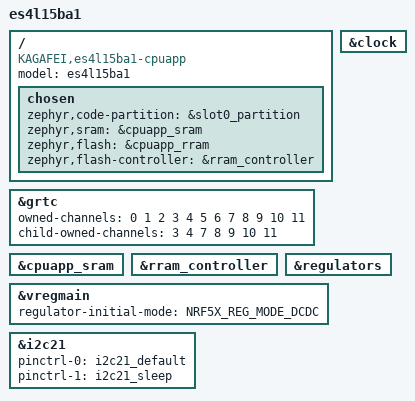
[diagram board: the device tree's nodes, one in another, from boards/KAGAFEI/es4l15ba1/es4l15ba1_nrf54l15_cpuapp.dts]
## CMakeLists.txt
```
cmake_minimum_required(VERSION 3.20.0)

# The kneil_tinyml library (src/kneil_*.c, include/, zephyr/module.yml) is in this folder,
# so this folder is also its Zephyr module. The library builds only if CONFIG_KNEIL_TINYML=y.
list(APPEND ZEPHYR_EXTRA_MODULES ${CMAKE_CURRENT_SOURCE_DIR})

find_package(Zephyr REQUIRED HINTS $ENV{ZEPHYR_BASE})

project(neilv2)

if(CONFIG_NEIL_APP_KNEIL_LIVE)
    # KNEIL live build (kneil.conf): activity classifier and live stream over BLE
    target_sources(app PRIVATE
        src/kneil_live.c
        src/bma580_fifo.c
        protocol/kneil_proto.c
    )
    target_include_directories(app PRIVATE protocol)

    # Model size for the INFO lines, counted in the generated headers (never edited): a tree with
    # k decisions has 2k+1 nodes. CMake runs again if a model header changes.
    foreach(model forest tree)
        set(model_h ${CMAKE_CURRENT_SOURCE_DIR}/include/kneil_model_${model}.h)
        file(STRINGS ${model_h} decisions REGEX "if \\(features\\[")
        file(STRINGS ${model_h} trees REGEX "int32_t kneil_model_tree_[0-9]+\\(")
        list(LENGTH decisions n_decisions)
        list(LENGTH trees n_trees)
        math(EXPR n_nodes "2 * ${n_decisions} + ${n_trees}")
        string(TOUPPER ${model} MODEL)
        target_compile_definitions(app PRIVATE KNEIL_${MODEL}_TREES=${n_trees} KNEIL_${MODEL}_NODES=${n_nodes})
        set_property(DIRECTORY APPEND PROPERTY CMAKE_CONFIGURE_DEPENDS ${model_h})
    endforeach()
else()
    # NeiL BLE sensor app
    target_sources(app PRIVATE
        src/main.c
        src/rtc.c
        src/bma580.c
        src/TEMP118.c
    )
endif()

target_include_directories(app PRIVATE src)
```

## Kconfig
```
# NeiL application options. The kneil_tinyml library options are in zephyr/Kconfig.

config NEIL_APP_KNEIL_LIVE
	bool "KNEIL live app (src/kneil_live.c) instead of the NeiL BLE app (src/main.c)"
	help
	  Set in kneil.conf. Runs the kneil_tinyml activity classifier on the
	  BMA580 data and streams the results (KNEIL live protocol).

source "Kconfig.zephyr"
```

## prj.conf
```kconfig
# Console and Debug (for development - disable for production)
CONFIG_CONSOLE=n
CONFIG_PRINTK=n
CONFIG_RTT_CONSOLE=n
CONFIG_USE_SEGGER_RTT=n
CONFIG_SERIAL=n
CONFIG_UART_CONSOLE=n
CONFIG_LOG=n
CONFIG_ASSERT=n
CONFIG_DEBUG=n

# I2C Configuration
CONFIG_I2C=y

# 32kHz clock source: this module has no external 32.768kHz crystal fitted
# (see datasheet section 12, "Notes"), so the SoftDevice Controller/MPSL must
# be told to use the internal RC oscillator instead of an XTAL. Without this,
# the build fails in mpsl_init.c with "Clock source is not supported or not
# defined".
CONFIG_CLOCK_CONTROL_NRF_K32SRC_RC=y
CONFIG_CLOCK_CONTROL_NRF_K32SRC_RC_CALIBRATION=y
CONFIG_CLOCK_CONTROL_NRF_K32SRC_500PPM=y

# Bluetooth Configuration
# NOTE: CONFIG_BT_LL_SOFTDEVICE is selected by default on nRF54L, unlike the
# nRF52832 build this project was ported from (which used the Zephyr
# BT_LL_SW_SPLIT controller). TX power is therefore set with
# BT_CTLR_TX_PWR_ANTENNA (dBm) instead of the BT_CTLR_TX_PWR_PLUS_x choice.
CONFIG_BT=y
CONFIG_BT_DEVICE_NAME="NeiL V3"
CONFIG_BT_PERIPHERAL=y
CONFIG_BT_GATT_DYNAMIC_DB=n
CONFIG_BT_GATT_CACHING=n
CONFIG_BT_AUTO_PHY_UPDATE=n
CONFIG_BT_DATA_LEN_UPDATE=n
CONFIG_BT_SETTINGS=n
CONFIG_SETTINGS=n

# Power: without a preferred connection interval, most centrals (esp. iOS)
# default to a fast ~30-50ms interval, keeping the radio active far more
# often than this app needs (send_data_thread only has new data every
# NOTIFY_INTERVAL=100ms). CONFIG_BT_GAP_AUTO_UPDATE_CONN_PARAMS defaults to y
# and was previously being force-disabled here, which meant these preferred
# values were also never requested to the central.
CONFIG_BT_GAP_AUTO_UPDATE_CONN_PARAMS=y
CONFIG_BT_PERIPHERAL_PREF_MIN_INT=80
CONFIG_BT_PERIPHERAL_PREF_MAX_INT=160
CONFIG_BT_PERIPHERAL_PREF_LATENCY=0
CONFIG_BT_PERIPHERAL_PREF_TIMEOUT=400

# Reduce CPU frequency when idle
CONFIG_SYS_CLOCK_TICKS_PER_SEC=100

# Disable features not needed
CONFIG_TIMESLICING=n

# Sensor Support
CONFIG_SENSOR=y

# GPIO Configuration
CONFIG_GPIO=n

# Standard C Library
CONFIG_NEWLIB_LIBC=y

# Power Management
# NOTE: CONFIG_PM/CONFIG_PM_DEVICE are left out here: the nRF54L SoC family
# does not select HAS_PM in this NCS version (only nRF54H does), so setting
# them is a silently-dropped no-op that just produces a Kconfig warning.
CONFIG_HWINFO=y
CONFIG_POWEROFF=y

# Bluetooth Device Information Service
# NOTE: CONFIG_BT_DIS_MANUF/CONFIG_BT_DIS_MODEL are deprecated in this Zephyr
# version; use the *_NAME_STR / *_NUMBER_STR equivalents instead.
CONFIG_BT_DIS=y
CONFIG_BT_DIS_MANUF_NAME_STR="NEIL TECH LTD"
CONFIG_BT_DIS_MODEL_NUMBER_STR="NeiL V01"

# Memory optimization
CONFIG_MAIN_STACK_SIZE=2048

# ===== POWER OPTIMIZATION SETTINGS =====
# Request +4 dBm TX power (SoftDevice Controller antenna power, in dBm)
CONFIG_BT_CTLR_TX_PWR_ANTENNA=4
```

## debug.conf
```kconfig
# Debug overlay: re-enables the RTT console/printk/logging that prj.conf
# turns off for the power-optimized production build. Build with this on top
# of prj.conf, e.g.:
#   west build -b es4l15ba1/nrf54l15/cpuapp -- -DEXTRA_CONF_FILE=debug.conf
CONFIG_CONSOLE=y
CONFIG_PRINTK=y
CONFIG_USE_SEGGER_RTT=y
CONFIG_RTT_CONSOLE=y
CONFIG_LOG=y
CONFIG_ASSERT=y
CONFIG_DEBUG=y

# Needed for the RTC INT-pin GPIO monitoring diagnostic (main.c int_gpio).
CONFIG_GPIO=y

# The default 1 kB RTT up-buffer overflows during the dense boot-time sensor
# probe (the host logger only drains ~2 kB/s), silently dropping lines.
CONFIG_SEGGER_RTT_BUFFER_SIZE_UP=8192
```

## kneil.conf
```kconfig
# KNEIL live build for the es4l15ba1 board: activity classifier (kneil_tinyml, model V3).
# Use it on top of prj.conf, in its own build folder (the NeiL app in main.c is not changed):
#   west build -d build_kneil -b es4l15ba1/nrf54l15/cpuapp . -- -DBOARD_ROOT=. -DEXTRA_CONF_FILE=kneil.conf

# Build src/kneil_live.c instead of src/main.c
CONFIG_NEIL_APP_KNEIL_LIVE=y

# kneil_tinyml library
CONFIG_KNEIL_TINYML=y
CONFIG_KNEIL_TINYML_FS_HZ=50
CONFIG_KNEIL_TINYML_SELFTEST=y
CONFIG_FPU=y
CONFIG_FPU_SHARING=y

# Bluetooth LE: advertises KNEIL-xxxx with the KNEIL live service (LIVE, RAW, CONTROL).
# ATT MTU 247 and data length extension (prj.conf turns these updates off for the NeiL app).
CONFIG_BT_DEVICE_NAME_DYNAMIC=y
CONFIG_BT_DEVICE_NAME_MAX=16
CONFIG_BT_L2CAP_TX_MTU=247
CONFIG_BT_BUF_ACL_TX_SIZE=251
CONFIG_BT_BUF_ACL_RX_SIZE=251
CONFIG_BT_CTLR_DATA_LENGTH_MAX=251
CONFIG_BT_DATA_LEN_UPDATE=y
CONFIG_BT_AUTO_PHY_UPDATE=y
# margin for the Bluetooth RX thread (GATT callbacks run on it; 1024 overflowed once)
CONFIG_BT_RX_STACK_SIZE=2048

# A fault restarts the board instead of halting it (the bridge reconnects by itself); the fault report
# is printed on RTT and the INFO summary shows the reset cause.
CONFIG_RESET_ON_FATAL_ERROR=y
CONFIG_LOG=y
CONFIG_LOG_MODE_MINIMAL=y
CONFIG_LOG_DEFAULT_LEVEL=2

# Diagnostics only over SEGGER RTT (this board has no UART or USB; tests use BLE and the bridge)
CONFIG_CONSOLE=y
CONFIG_PRINTK=y
CONFIG_USE_SEGGER_RTT=y
CONFIG_RTT_CONSOLE=y
CONFIG_SEGGER_RTT_BUFFER_SIZE_UP=4096
```

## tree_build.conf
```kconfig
# Extra Kconfig fragment for the single-tree KNEIL live build (adds to kneil.conf):
#   west build -d build_kneil_tree -b es4l15ba1/nrf54l15/cpuapp . --pristine=always -- \
#       "-DBOARD_ROOT=<absolute path of this folder>" "-DEXTRA_CONF_FILE=kneil.conf;tree_build.conf"
CONFIG_KNEIL_TINYML_MODEL_SMALL=y
```

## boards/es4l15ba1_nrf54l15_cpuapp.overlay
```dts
/*
 * App-level overlay for the custom board: run the I2C bus at 100 kHz
 * (I2C_BITRATE_STANDARD) instead of the driver default, to rule out bus
 * speed as a factor while debugging the sensors. Pin assignment and
 * everything else still comes from the board's own devicetree.
 */

&i2c21 {
	clock-frequency = <I2C_BITRATE_STANDARD>;
};
```

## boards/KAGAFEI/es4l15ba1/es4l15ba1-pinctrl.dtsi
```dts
&pinctrl {
	i2c21_default: i2c21_default {
		group1 {
			psels = <NRF_PSEL(TWIM_SDA, 1, 7)>,
					<NRF_PSEL(TWIM_SCL, 1, 6)>;
			bias-pull-up;
		};
	};

	i2c21_sleep: i2c21_sleep {
		group1 {
			psels = <NRF_PSEL(TWIM_SDA, 1, 7)>,
					<NRF_PSEL(TWIM_SCL, 1, 6)>;
			low-power-enable;
		};
	};
};
```

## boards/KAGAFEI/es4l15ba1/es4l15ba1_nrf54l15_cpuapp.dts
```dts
/dts-v1/;
#include <nordic/nrf54l15_cpuapp.dtsi>
#include <zephyr/dt-bindings/gpio/gpio.h>
#include <zephyr/dt-bindings/i2c/i2c.h>
#include "es4l15ba1-pinctrl.dtsi"

/ {
	model = "es4l15ba1";
	compatible = "KAGAFEI,es4l15ba1-cpuapp";

	chosen {
		zephyr,code-partition = &slot0_partition;
		zephyr,sram = &cpuapp_sram;
		zephyr,flash = &cpuapp_rram;
		zephyr,flash-controller = &rram_controller;
	};
};

&grtc {
	owned-channels = <0 1 2 3 4 5 6 7 8 9 10 11>;
	/* Channels 7-11 reserved for Zero Latency IRQs, 3-4 for FLPR */
	child-owned-channels = <3 4 7 8 9 10 11>;
	status = "okay";
};

&cpuapp_sram {
	status = "okay";
};

&rram_controller {
	status = "okay";
};

/*
 * Required for the CLOCK_CONTROL_NRF Kconfig menu (32kHz clock source
 * selection) to be visible at all - see prj.conf for why the RC oscillator
 * is selected as the LFCLK source on this crystal-less module.
 */
&clock {
	status = "okay";
};

/*
 * Switch the main regulator from the default LDO to DC/DC mode. The
 * datasheet requires a 4.7uH inductor across PAD2 (DECD) / PAD21 (DCC) for
 * exactly this purpose (section 11.2.3) - without this, that inductor is
 * populated on the board but unused, and the SoC runs on the less efficient
 * LDO the whole time, most noticeably during radio TX.
 */
&regulators {
	status = "okay";
};

&vregmain {
	status = "okay";
	regulator-initial-mode = <NRF5X_REG_MODE_DCDC>;
};

&i2c21 {
	status = "okay";
	pinctrl-0 = <&i2c21_default>;
	pinctrl-1 = <&i2c21_sleep>;
	pinctrl-names = "default", "sleep";
};

#include <nordic/nrf54l15_partition.dtsi>
```

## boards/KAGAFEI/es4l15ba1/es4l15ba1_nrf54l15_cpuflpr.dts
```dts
/dts-v1/;
#include <nordic/nrf54l15_cpuflpr.dtsi>
#include "es4l15ba1-pinctrl.dtsi"

/ {
	model = "es4l15ba1";
	compatible = "KAGAFEI,es4l15ba1-cpuflpr";

	chosen {
		zephyr,code-partition = &cpuflpr_code_partition;
		zephyr,flash = &cpuflpr_rram;
		zephyr,sram = &cpuflpr_sram;
	};
};

&cpuflpr_sram {
	status = "okay";
	reg = <0x20028000 DT_SIZE_K(96)>;
	ranges = <0x0 0x20028000 DT_SIZE_K(96)>;
};

&cpuflpr_rram {
	partitions {
		compatible = "fixed-partitions";
		#address-cells = <1>;
		#size-cells = <1>;

		cpuflpr_code_partition: partition@0 {
			label = "image-0";
			reg = <0x0 DT_SIZE_K(96)>;
		};
	};
};

&grtc {
	owned-channels = <3 4>;
	status = "okay";
};
```

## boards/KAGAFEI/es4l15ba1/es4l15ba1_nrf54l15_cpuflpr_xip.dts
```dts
#include "es4l15ba1_nrf54l15_cpuflpr.dts"

/ {
	compatible = "KAGAFEI,es4l15ba1-cpuflpr-xip";
};

&cpuflpr_sram {
	reg = <0x2002f000 DT_SIZE_K(68)>;
	ranges = <0x0 0x2002f000 DT_SIZE_K(68)>;
};
```

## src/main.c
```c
#include <zephyr/kernel.h>
#include <zephyr/device.h>
#include <zephyr/drivers/i2c.h>
#include <zephyr/sys/printk.h>
#include "bma580.h"
#include "TEMP118.h"
#include "RTC.h"
#include <zephyr/types.h>
#include <stddef.h>
#include <string.h>
#include <zephyr/bluetooth/bluetooth.h>
#include <zephyr/bluetooth/gap.h>
#include <zephyr/sys/printk.h>
#include <zephyr/sys/byteorder.h>
#include <zephyr/bluetooth/uuid.h>
#include <zephyr/bluetooth/gatt.h>

#include <zephyr/drivers/gpio.h>
#include <zephyr/drivers/hwinfo.h>
#include <zephyr/drivers/comparator.h>
#include <zephyr/pm/device.h>
#include <zephyr/sys/poweroff.h>
#include <zephyr/sys/util.h>

// Make sure the node label matches your device tree, e.g., "interrupt" or "button0"
//tatic const struct gpio_dt_spec sw0 = GPIO_DT_SPEC_GET(DT_NODELABEL(interrupt), gpios);
// If your device tree uses a different label (e.g., "button0"), use that instead:
// static const struct gpio_dt_spec sw0 = GPIO_DT_SPEC_GET(DT_NODELABEL(button0), gpios);

#define DEVICE_NAME     CONFIG_BT_DEVICE_NAME
#define DEVICE_NAME_LEN (sizeof(DEVICE_NAME) - 1)
#define NOTIFY_INTERVAL 100
// ES4L15BA1 (nRF54L15): I2C SCL/SDA are on P1.06/P1.07, wired to the i2c21
// TWIM/pinctrl instance in boards/KAGAFEI/es4l15ba1/es4l15ba1_nrf54l15_cpuapp.dts
// (the previous nRF52832 board used the "i2c0" node label instead).
#define I2C_DEV_NODE DT_NODELABEL(i2c21)
#define STACK_SIZE 1024
#define PRIORITY 5
#define BT_UUID_SENSOR_SERVICE_VAL \
	BT_UUID_128_ENCODE(0x00001000, 0x0000, 0x1000, 0x8000, 0x5f9b34fb)

// define DEF_SVC1_ADC_VAL_1_UUID_128      {0xFB, 0x34, 0x9B, 0x5F, 0x80, 0x00, 0x00, 0x80, 0x00, 0x10, 0x00, 0x00, 0x01, 0x10, 0x00, 0x00}
// 0000 1001-0000-1000-8000-00805F9B34FB
#define BT_UUID_SENSOR_CHAR_VAL \
	BT_UUID_128_ENCODE(0x00001001, 0x0000, 0x1000, 0x8000, 0x00805F9B34FB)

static bool notify_enabled = false;
static struct bt_uuid_128 sensor_service_uuid = BT_UUID_INIT_128(BT_UUID_SENSOR_SERVICE_VAL);
static struct bt_uuid_128 sensor_char_uuid = BT_UUID_INIT_128(BT_UUID_SENSOR_CHAR_VAL);
#define I2C_ADDR 0x18  // Replace with your target device address
static const uint8_t url_data[] = {
    0x17,'/' ,'/',
    'w','w','w','.','n','e','i','l','.','t','e','c','h','/'
};
static struct k_work adv_work;
static bool is_connected = false;
static uint8_t sensor_data[20];
static const struct bt_data ad[]={
	BT_DATA_BYTES(BT_DATA_UUID128_ALL, BT_UUID_SENSOR_SERVICE_VAL),
	BT_DATA_BYTES(BT_DATA_FLAGS, BT_LE_AD_GENERAL | BT_LE_AD_NO_BREDR),
	BT_DATA(BT_DATA_NAME_COMPLETE, DEVICE_NAME, DEVICE_NAME_LEN),
};

const struct device *i2c_dev = DEVICE_DT_GET(I2C_DEV_NODE);


static const struct bt_data sd[]={

	//BT_DATA_BYTES(BT_DATA_UUID128_ALL, BT_UUID_SENSOR_SERVICE_VAL),
	BT_DATA(BT_DATA_URI,url_data,sizeof(url_data)),

};
static const struct bt_le_adv_param *adv_param = BT_LE_ADV_PARAM(
	(BT_LE_ADV_OPT_CONN |
	 BT_LE_ADV_OPT_USE_IDENTITY),
	640,
	800,
	NULL);

/* Wakes send_data_thread when it may have work to do (connected AND
 * notifications enabled), instead of it polling is_connected/notify_enabled
 * on a 20ms timer. */
static K_SEM_DEFINE(notify_state_sem, 0, 1);

static void sensor_ccc_cfg_changed(const struct bt_gatt_attr *attr, uint16_t value)
{
	notify_enabled = (value & BT_GATT_CCC_NOTIFY);
	printk("Notify %s\n", notify_enabled ? "enabled" : "disabled");
	k_sem_give(&notify_state_sem);
}

BT_GATT_SERVICE_DEFINE(sensor_svc,
	BT_GATT_PRIMARY_SERVICE(&sensor_service_uuid),
	BT_GATT_CHARACTERISTIC(&sensor_char_uuid.uuid,
			           BT_GATT_CHRC_NOTIFY | BT_GATT_CHRC_READ,
                       BT_GATT_PERM_READ,
			       NULL, NULL, sensor_data),
	BT_GATT_CCC(sensor_ccc_cfg_changed,
		    BT_GATT_PERM_READ | BT_GATT_PERM_WRITE),
);


static void adv_work_handler(struct k_work *work){
	int err = bt_le_adv_start(adv_param, ad, ARRAY_SIZE(ad), sd, ARRAY_SIZE(sd));

	if (err) {
		printk("Advertising failed to start (err %d)\n", err);
		return;
	}

	printk("Advertising successfully started\n");
}

static void advertising_start(void){
	k_work_submit(&adv_work);
}
static void recycled_cb(void){
	printk("Connection object available from previous conn. Disconnect is complete!\n");
	advertising_start();
}

static void on_connected(struct bt_conn *conn, uint8_t err){
	if (err) {
		printk("Connection failed (err %u)\n", err);
		return;
	}
	/* Powering the sensors up costs ~100ms of blocking k_sleep()s, which is
	 * far too long to spend inside a Bluetooth callback - it stalls the BT
	 * RX thread. Just record the state and let send_data_thread do the work. */
	is_connected = true;
	k_sem_give(&notify_state_sem);
	printk("Connected\n");
}

static void on_disconnected(struct bt_conn *conn, uint8_t reason){
	is_connected = false;
	notify_enabled = false;
	/* Wake send_data_thread so it powers both sensors down. Doing it there
	 * rather than here also avoids racing with an in-flight sensor read. */
	k_sem_give(&notify_state_sem);
	printk("Disconnected (reason %u)\n", reason);
}

struct bt_conn_cb connection_callbacks = {
	.connected = on_connected,
	.disconnected = on_disconnected,
	.recycled = recycled_cb,
};

/* Tracks whether the two sensors are currently powered. Owned exclusively by
 * send_data_thread so that they are woken exactly once when a central
 * connects and shut down exactly once when it goes away. */
static bool sensors_on;

static void sensors_power_up(void)
{
	TMP_wakeup(i2c_dev);
	k_msleep(20);
	BMA580_init(i2c_dev);
	k_msleep(20);
	sensors_on = true;
	printk("Sensors powered up\n");
}

static void sensors_power_down(void)
{
	TMP_sleep(i2c_dev);
	BMA_sleep(i2c_dev);
	sensors_on = false;
	printk("Sensors powered down\n");
}

void send_data_thread(void)
{

	if (!device_is_ready(i2c_dev)) {
    printk("I2C device not ready!\n");
    return;
	}

	k_msleep(20);

	/* Nothing is connected at boot, so put both sensors into their idle
	 * state rather than leaving them in whatever mode they came up in -
	 * the TMP118 in particular powers up converting continuously. */
	sensors_power_down();

	while (1) {
		if (is_connected) {
			if (!sensors_on) {
				sensors_power_up();
			}

			if (notify_enabled) {
				uint8_t data_temp[2];
				uint8_t data_xyz[6];
				uint8_t packet[20] = {0};

				readAccel(i2c_dev, data_xyz);
				k_msleep(50);
				readTemp118(i2c_dev, data_temp);

				packet[3] = data_temp[0];
				packet[4] = data_temp[1];
				//uint8_t zero = 0;
				for (int i = 0; i < 6; i++) {
					packet[14 + i] = data_xyz[i];
				}
				memcpy(sensor_data, packet, sizeof(packet));
				bt_gatt_notify(NULL, &sensor_svc.attrs[2], sensor_data, sizeof(packet));
				k_sleep(K_MSEC(NOTIFY_INTERVAL));
				continue;
			}
		} else if (sensors_on) {
			sensors_power_down();
		}

		/* Either disconnected, or connected but not subscribed yet: there is
		 * nothing to sample until the connection/notify state changes. */
		k_sem_take(&notify_state_sem, K_FOREVER);
	}
}

K_THREAD_DEFINE(sensor_thread_id, STACK_SIZE,
		send_data_thread, NULL, NULL, NULL,
		PRIORITY, 0, 0);

/*void print_time_thread(void)
{
    if (!device_is_ready(i2c_dev)) {
        printk("I2C device not ready!\n");
        return;
    }

    while (1) {
        uint8_t seconds, minutes, hours, date, month, year;

        // Use the new RTC function
        RTC_read_time(i2c_dev, &seconds, &minutes, &hours, &date, &month, &year);

        // Convert BCD to decimal
        uint8_t sec = ((seconds >> 4) * 10) + (seconds & 0x0F);
        uint8_t min = ((minutes >> 4) * 10) + (minutes & 0x0F);
        uint8_t hr = ((hours >> 4) * 10) + (hours & 0x0F);
        uint8_t d = ((date >> 4) * 10) + (date & 0x0F);
        uint8_t mon = ((month >> 4) * 10) + (month & 0x0F);
        uint8_t yr = ((year >> 4) * 10) + (year & 0x0F);

        // Print time
        printk("RTC Time: 20%02d-%02d-%02d %02d:%02d:%02d\n",
               yr, mon, d, hr, min, sec);

        k_sleep(K_SECONDS(1));
    }
}

// Add thread definition before main()
K_THREAD_DEFINE(print_time_thread_id, STACK_SIZE,
        print_time_thread, NULL, NULL, NULL,
        PRIORITY, 0, 0);*/

int main(void)
{
	//printk("\n%s system off demo\n", CONFIG_BOARD);

	//*(volatile uint32_t *)0x40000578 = 1;

	//RTC_clkout_disable(i2c_dev);
	//RTC_enable_porie_interrupt(i2c_dev);


	int alarm_status;

	if (!device_is_ready(i2c_dev)) {
        printk("I2C device not ready!\n");
        return 0;
    }

	alarm_status = RTC_Check_Alarm(i2c_dev);
	RTC_debug_dump(i2c_dev, "boot, before set_datetime");
	if (alarm_status == 1){
		printk("Alarm Date not set\n");
		RTC_set_datetime(i2c_dev,2025,1,26,1,12,0,0);
		printk("\n Date set \n");
		RTC_debug_dump(i2c_dev, "after set_datetime");
	}

	int err = bt_enable(NULL);

	if (err){
		printk("BLE Intialise Fail\n");
	}
	printk("Bluetooth initialized\n");
	bt_conn_cb_register(&connection_callbacks);
	k_work_init(&adv_work, adv_work_handler);
	advertising_start();

	k_sleep(K_SECONDS(20)); // Run for 1200 seconds 20 minutes
	// RTC_Start_CountDown(i2c_dev);
	k_thread_abort(sensor_thread_id);
	/* The thread owned the sensors; now that it is gone, make sure they are
	 * idle in case the load switch does not actually cut power. */
	sensors_power_down();

	if (alarm_status == 1){
		RTC_alarm_init(i2c_dev,1);
	}
	else {
		RTC_recover_int(i2c_dev);
	}
	RTC_debug_dump(i2c_dev, "after alarm branch");
	return 0;
	/*
	 * The RTC's alarm output isn't wired to this MCU - it drives a load
	 * switch that cuts power to this whole board. There is therefore no
	 * wake source for this SoC to arm: once the switch re-applies power,
	 * the SoC just goes through a normal power-on reset and main() runs
	 * again from scratch. All that's left to do here is stop spending
	 * power for however long remains until the RTC's alarm actually
	 * fires and the switch cuts power, so disable BLE and drop into the
	 * lowest-current System OFF state.
	 */
	//bt_disable();
	//sys_poweroff();
}
```

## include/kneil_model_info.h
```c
/* Written by stage3.py (KNEIL virtual implant) together with the model headers. */
#ifndef KNEIL_MODEL_INFO_H
#define KNEIL_MODEL_INFO_H
#define KNEIL_MODEL_FS_HZ 50          /* the models were trained on 50 Hz data */
#define KNEIL_MODEL_N_FEATURES 20
#define KNEIL_MODEL_LOWPASS_HZ 6      /* input low-pass used in training, applied on the device (0 = off) */
#define KNEIL_MODEL_DATASET "kneil_dataset_v1_6; kneil_camargo_v1_3; caicedo_2020; real implant-site (CeTI, KneE-PAD, MHEALTH, Marpino, PAMAP2, WearGait-PD); V3"
#endif
```

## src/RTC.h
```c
#ifndef RTC_H
#define RTC_H


#include <stdint.h>
#include <zephyr/device.h>

//void RTC_init_ContDown(const struct device *dev);
//void RTC_Start_CountDown(const struct device *dev);

int RTC_set_datetime(const struct device *i2c,
                     uint16_t year, uint8_t month, uint8_t date, uint8_t weekday,
                     uint8_t hour24, uint8_t minute, uint8_t second);
int RTC_alarm_init(const struct device *dev, uint8_t mins);

//void RTC_alarm_set(const struct device *dev);
//void RTC_recover_int(const struct device *dev);

int RTC_clkout_disable(const struct device *dev);

int RTC_enable_porie_interrupt(const struct device *dev);

int RTC_set_to_build_time(const struct device *i2c);

void RTC_read_time(const struct device *dev, uint8_t *seconds, uint8_t *minutes,
                   uint8_t *hours, uint8_t *date, uint8_t *month, uint8_t *year);

int RTC_Check_Alarm(const struct device *dev);

void RTC_recover_int(const struct device *dev);

void RTC_debug_dump(const struct device *dev, const char *label);
#endif
```

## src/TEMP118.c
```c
#include "TEMP118.h"
#include <zephyr/kernel.h>
#include <zephyr/device.h>
#include <zephyr/drivers/i2c.h>
#include <zephyr/sys/printk.h>
#include <string.h>

#define Temp_Data            0x00
#define TEMP118_Addr         0x49
#define TEMP118_config       0x01

#define ShutDown_Mode_MSB        0x61
#define ShutDown_Mode_LSB        0xB0
#define Continue_Mode_MSB        0x60
#define Continue_Mode_LSB        0xB0



void readTemp118(const struct device *dev, uint8_t *  temp){

uint8_t reg = Temp_Data ;
uint8_t data[2];
   int ret = i2c_write_read(dev,TEMP118_Addr,&reg,1,data,sizeof(data));
 if (ret < 0) {
        printk("[TMP] R 0x%02X reg=0x%02X len=2 -> FAIL %d\n",
               TEMP118_Addr, reg, ret);
        return;
    }
    printk("[TMP] R 0x%02X reg=0x%02X len=2 -> 0x%02X 0x%02X\n",
           TEMP118_Addr, reg, data[0], data[1]);
   memcpy(temp,data,sizeof(data));
     printk("Temp data: %02X %02X \n",
       data[0], data[1]);
}
static int write_reg(const struct device *dev, uint8_t reg, uint8_t data_MSB,uint8_t data_LSB)
{
    uint8_t buf[3] = {reg, data_MSB,data_LSB};
    int ret = i2c_write(dev, buf, sizeof(buf), TEMP118_Addr);

    if (ret < 0) {
        printk("[TMP] W 0x%02X reg=0x%02X data=0x%02X%02X -> FAIL %d\n",
               TEMP118_Addr, reg, data_MSB, data_LSB, ret);
    } else {
        printk("[TMP] W 0x%02X reg=0x%02X data=0x%02X%02X -> ok\n",
               TEMP118_Addr, reg, data_MSB, data_LSB);
    }

    return ret;
}
void TMP_sleep(const struct device *dev){

int ret = write_reg(dev,TEMP118_config,ShutDown_Mode_MSB,ShutDown_Mode_LSB);
if (ret < 0) {
        printk("sleep failed\n");

}
}
void TMP_wakeup(const struct device *dev){

int ret = write_reg(dev,TEMP118_config,Continue_Mode_MSB,Continue_Mode_LSB);

if (ret < 0) {
        printk("sleep wake up\n");

}
}
```

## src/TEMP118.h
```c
#ifndef TEMP118_H
#define TEMP118_H


#include <stdint.h>
#include <zephyr/device.h>


void readTemp118(const struct device *dev, uint8_t *temp);
void readtempAS(uint8_t *data_xyz);
void TMP_sleep(const struct device *dev);
void TMP_wakeup(const struct device *dev);








#endif
```

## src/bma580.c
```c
#include "bma580.h"
#include <zephyr/kernel.h>
#include <zephyr/device.h>
#include <zephyr/drivers/i2c.h>
#include <zephyr/sys/printk.h>
#include <string.h>
#include <errno.h>

#define BMA580_Addr                     0x18
#define BMA580_CHIP_ID                  0x00
#define BMA580_CHIP_ID_VAL              0xC4
#define BMA580_INT2_CONF                0x35
#define BMA580_ACC_CONF_0				0x30  //default 0x0F
#define BMA580_ACC_CONF_1				0x31 	// 0xA8 high power mode, normal mode , 400 hz
#define BMA580_ACC_CONF_2				0x32  // defalt 0x0E
#define BMA580_ACC_DATA_0				0x18
#define BMA580_ACC_DATA_1				0x19
#define BMA580_ACC_DATA_2				0x1A
#define BMA580_ACC_DATA_3				0x1B
#define BMA580_ACC_DATA_4				0x1C
#define BMA580_ACC_DATA_5				0x1D
#define BMA580_Tem_DATA					0x1E
// #define BMA580_cmd_SUSPEND				0x1E // <-- This was incorrect, 0x1E is TEMP_DATA
#define BMA580_CMD_SUSPEND				0x04 // <-- Correct register (CMD_SUSPEND) from datasheet p. 68
#define BMA580_CMD_RESET				0x7E
#define BMA580_acc_STATUS				0x11


static int write_reg(const struct device *dev, uint8_t reg, uint8_t data)
{
    uint8_t buf[2] = {reg, data};
    int ret = i2c_write(dev, buf, sizeof(buf), BMA580_Addr);

    if (ret < 0) {
        printk("[BMA] W 0x%02X reg=0x%02X data=0x%02X -> FAIL %d\n",
               BMA580_Addr, reg, data, ret);
    } else {
        printk("[BMA] W 0x%02X reg=0x%02X data=0x%02X -> ok\n",
               BMA580_Addr, reg, data);
    }
    return ret;
}

/**
 * @brief Waits until the BMA580 answers on I2C after power-on or a soft reset.
 * @note Datasheet p. 14: after power-on or soft reset, the first I2C access only selects the
 *       interface and is not acknowledged (NACK). On this board the next access can fail too, so
 *       CHIP_ID is read until it returns 0xC4 (at most 10 tries, 2 ms apart).
 * @return 0 when the sensor answers, -EIO otherwise.
 */
static int BMA_wait_chip_id(const struct device *dev)
{
    uint8_t reg = BMA580_CHIP_ID;
    uint8_t id = 0;

    for (int attempt = 1; attempt <= 10; attempt++) {
        if (i2c_write_read(dev, BMA580_Addr, &reg, 1, &id, 1) == 0 && id == BMA580_CHIP_ID_VAL) {
            printk("[BMA] chip id 0x%02X after %d attempt(s)\n", id, attempt);
            return 0;
        }
        k_sleep(K_MSEC(2));
    }
    printk("[BMA] no answer to chip id read (last 0x%02X)\n", id);
    return -EIO;
}

/**
 * @brief Performs a soft-reset on the BMA580.
 * @note Per datasheet section 4.1, the device enters SUSPEND mode after a reset.
 */
void BMA_soft_reset(const struct device *dev){
    k_sleep(K_MSEC(20));
    // Write 0xB6 to CMD register 0x7E to trigger soft-reset
    write_reg(dev, BMA580_CMD_RESET, 0xB6);
    // Wait for device to reboot (datasheet p. 22, power on time is ~1.8ms)
    k_sleep(K_MSEC(50));
    // Select I2C again (the first access after a reset is not acknowledged), see BMA_wait_chip_id()
    BMA_wait_chip_id(dev);
}

/**
 * @brief Wakes the BMA580 from SUSPEND mode to ACTIVE mode.
 * @note This is done by writing 0x00 to the CMD_SUSPEND register (0x04).
 */
void BMA_wakeup(const struct device *dev){
    // Write 0x00 to CMD_SUSPEND register (0x04) to disable suspend mode
    int ret = write_reg(dev, BMA580_CMD_SUSPEND, 0x00);
    if (ret < 0) {
        printk("BMA580 failed to enter ACTIVE mode (wakeup)\n");
    }
    // Give the sensor time to start up (datasheet p. 26, ~3.15ms)
    k_sleep(K_MSEC(5));
}


void BMA580_init(const struct device *dev)
{
    if (!device_is_ready(dev)) {
        printk("BMA580 I2C device not ready\n");
        return;
    }

    // 1. Reset the device. This leaves it in SUSPEND mode.
    BMA_soft_reset(dev);

    // 2. Wake the device up to ACTIVE mode.
    BMA_wakeup(dev);

    // 2b. I2C is used: configure INT2 (pin 3, CSB in SPI mode) as an output, as the datasheet
    //     recommends (section 5.2.1.1), so the pin cannot trigger an erroneous SPI detection.
    write_reg(dev, BMA580_INT2_CONF, 0x01);

    // 3. Configure the sensor (as per datasheet Figure 6)
    write_reg(dev, BMA580_ACC_CONF_0, 0x00);           // Disable accelerometer to change config
    write_reg(dev, BMA580_ACC_CONF_1, 0xA5);           // ODR 50Hz (acc_odr=0x5), Normal filter, HPM
    write_reg(dev, BMA580_ACC_CONF_2, 0x0E);           // Range +/- 8g (acc_range=0b10, 4096 LSB/g), Roll-off -60dB
    write_reg(dev, BMA580_ACC_CONF_0, 0x0F);           // Enable accelerometer

    k_sleep(K_MSEC(10));  // Allow configuration to settle
}



void readAccel(const struct device *dev, uint8_t *data_xyz)
{
    uint8_t data[6];
    uint8_t reg = BMA580_ACC_DATA_0;
    uint8_t status_reg = BMA580_acc_STATUS;
    uint8_t flag = 0;
    int retries = 2;

while (retries-- > 0) {
    int err = i2c_write_read(dev, BMA580_Addr, &status_reg, 1, &flag, 1);
    if (err < 0) {
        printk("[BMA] R 0x%02X reg=0x%02X (status) -> FAIL %d\n",
               BMA580_Addr, status_reg, err);
        return;
    }
    printk("[BMA] R 0x%02X reg=0x%02X (status) -> 0x%02X\n",
           BMA580_Addr, status_reg, flag);
    // Check acc_data_rdy bit (bit 0 of SENSOR_STATUS 0x11)
    if (flag & 0x01) {
        break;
    } else {
        printk("data not ready\n");
        k_sleep(K_MSEC(5));
    }
}

// If still not ready after retries
if (!(flag & 0x01)) {
    printk("Timeout, forcing reset\n");
    BMA_soft_reset(dev);      // Soft reset
    k_sleep(K_MSEC(20));
    BMA580_init(dev);         // Reapply config
    return;
}

    int ret = i2c_write_read(dev, BMA580_Addr, &reg, 1, data, sizeof(data));
    if (ret < 0) {
        printk("[BMA] R 0x%02X reg=0x%02X len=6 (accel) -> FAIL %d\n",
               BMA580_Addr, reg, ret);
        return;
    }
    printk("[BMA] R 0x%02X reg=0x%02X len=6 (accel) -> ok\n", BMA580_Addr, reg);

    memcpy(data_xyz, data, sizeof(data));
    printk("Accel data: %02X %02X %02X %02X %02X %02X\n",
           data_xyz[0], data_xyz[1], data_xyz[2],
           data_xyz[3], data_xyz[4], data_xyz[5]);
}


void readtemp(const struct device *dev, uint8_t * const temp)
{
    uint8_t reg = BMA580_Tem_DATA;
    uint8_t buf[2];

    int ret = i2c_write_read(dev, BMA580_Addr, &reg, 1, buf, 2);
    if (ret < 0) {
        printk("[BMA] R 0x%02X reg=0x%02X len=2 (temp) -> FAIL %d\n",
               BMA580_Addr, reg, ret);
        return;
    }
    printk("[BMA] R 0x%02X reg=0x%02X len=2 (temp) -> ok\n", BMA580_Addr, reg);
       printk("Temp data: %02X %02X \n", // Corrected printk message
           buf[0], buf[1]);
   memcpy(temp, buf, sizeof(buf));
}

/**
 * @brief Puts the BMA580 into SUSPEND mode.
 * @note This is done by writing 0x01 to the CMD_SUSPEND register (0x04).
 */
void BMA_sleep(const struct device *dev)
{
    // Write 0x01 to CMD_SUSPEND register (0x04) to enable suspend mode
    int ret = write_reg(dev, BMA580_CMD_SUSPEND, 0x01);
    if (ret < 0) {
        printk("BMA580 failed to enter suspend mode\n");
    }
    k_sleep(K_MSEC(2)); // Allow time for the mode to change
}
```

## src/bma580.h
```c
#ifndef BMA580_H
#define BMA580_H

#include <stdint.h>
#include <zephyr/device.h>
void BMA580_init(const struct device *dev);
void readAccel(const struct device *dev, uint8_t *data_xyz);
void readtemp(const struct device *dev, uint8_t * const temp);
void BMA_wakeup(const struct device *dev);
void BMA_sleep(const struct device *dev);
#endif // BMA580_H
```

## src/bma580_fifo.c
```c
/* BMA580 start-up and FIFO streaming (see bma580_fifo.h). Register details: BMA580 datasheet
 * (BST-BMA580-DS000-05): start-up procedure p. 14, FIFO section 4.6, register map. */
#include <errno.h>
#include <zephyr/kernel.h>
#include <zephyr/drivers/i2c.h>
#include <zephyr/sys/printk.h>
#include <zephyr/sys/util.h>

#include "bma580_fifo.h"

#define BMA580_ADDR        0x18
#define REG_CHIP_ID        0x00
#define REG_HEALTH_STATUS  0x02
#define REG_CMD_SUSPEND    0x04
#define REG_ACC_CONF_0     0x30
#define REG_ACC_CONF_1     0x31
#define REG_ACC_CONF_2     0x32
#define REG_INT2_CONF      0x35
#define REG_FEAT_ENG_CONF  0x50
#define REG_CMD            0x7E
#define REG_FIFO_LEVEL_0   0x22   /* fill level in bytes (data only, headers are not stored) */
#define REG_FIFO_DATA_OUT  0x24   /* burst read: the address does not increment */
#define REG_FIFO_CTRL      0x40
#define REG_FIFO_CONF_0    0x41
#define REG_FIFO_CONF_1    0x42

#define CHIP_ID_BMA580     0xC4
#define CMD_SOFTRESET      0xB6
#define ACC_CONF_0_OFF     0x00   /* accelerometer off while it is configured */
#define ACC_CONF_0_ON      0x0F   /* accelerometer on (reset value) */
#define ACC_CONF_1_VAL     0xA5   /* HPM, normal filter, ODR 50 Hz (same as BMA580_init in bma580.c) */
#define ACC_CONF_2_VAL     0x0E   /* +/-8 g, IIR roll-off -60 dB */
#define FIFO_CTRL_RST      0x01
#define FIFO_CONF_0_VAL    0x0F   /* fifo_cfg = 1, x, y, z on, no compression */
#define FIFO_CONF_1_VAL    0x03   /* 1024 bytes, no sensor time, stop_on_full = 0 (oldest frame dropped) */

#define FIFO_SIZE          1024
#define PAYLOAD            6      /* x, y, z: 2 bytes each, LSB first */
#define FRAME              (1 + PAYLOAD)
#define FIFO_FULL_LEVEL    (FIFO_SIZE - 2 * PAYLOAD)   /* datasheet 4.6.1.4 */
#define HDR_ACC_XYZ        0xCE   /* const_1, frame_type = acceleration, z/y/x enabled */
#define HDR_EMPTY          0x80   /* FIFO empty */

static int reg_write(const struct device *i2c, uint8_t reg, uint8_t val)
{
	const uint8_t buf[2] = {reg, val};

	return i2c_write(i2c, buf, sizeof(buf), BMA580_ADDR);
}

static int reg_read(const struct device *i2c, uint8_t reg, uint8_t *buf, uint32_t len)
{
	return i2c_burst_read(i2c, BMA580_ADDR, reg, buf, len);
}

/* After power-on or soft reset, the first I2C transaction only selects the interface and is not
 * acknowledged (datasheet p. 14). On this board more than one access can fail, so CHIP_ID is read
 * until it answers. Returns the number of attempts (1..10), or a negative error. */
static int wait_chip_id(const struct device *i2c, uint8_t *id)
{
	int err = -EIO;

	for (int attempt = 1; attempt <= 10; attempt++) {
		err = reg_read(i2c, REG_CHIP_ID, id, 1);
		if (err == 0 && *id == CHIP_ID_BMA580) {
			return attempt;
		}
		k_msleep(2);
	}
	return err ? err : -ENODEV;
}

/* write, then report which register failed */
#define CHECK_WRITE(reg, val)                                                                      \
	do {                                                                                       \
		const int e_ = reg_write(i2c, (reg), (val));                                       \
		if (e_) {                                                                          \
			printk("I,bma580 write reg 0x%02x failed err=%d\n", (reg), e_);           \
			return e_;                                                                 \
		}                                                                                  \
	} while (0)

int bma580_fifo_start(const struct device *i2c)
{
	uint8_t id = 0, health = 0, acc[3], fifo[2];
	int err;

	/* datasheet start-up: soft reset, wait, select I2C, CHIP_ID, leave suspend, health */
	err = wait_chip_id(i2c, &id);                        /* in case the sensor was just powered */
	if (err < 0) {
		printk("I,bma580 no answer before reset: chip id 0x%02x err=%d\n", id, err);
	}
	(void)reg_write(i2c, REG_CMD, CMD_SOFTRESET);
	k_msleep(5);                                         /* power-on time 1.8 ms, 3 ms recommended */
	err = wait_chip_id(i2c, &id);
	if (err < 0) {
		printk("I,bma580 chip id 0x%02x err=%d (expected 0xc4)\n", id, err);
		return err;
	}
	printk("I,bma580 chip id 0xc4 after reset: %d attempt(s)\n", err);
	CHECK_WRITE(REG_CMD_SUSPEND, 0x00);                 /* SUSPEND -> ACTIVE */
	k_msleep(5);
	err = reg_read(i2c, REG_HEALTH_STATUS, &health, 1);
	if (err || (health & 0x0F) != 0x0F) {
		printk("I,bma580 health 0x%02x err=%d (expected 0x0f)\n", health, err);
		return err ? err : -EIO;
	}
	CHECK_WRITE(REG_INT2_CONF, 0x01);                   /* datasheet start-up step when I2C is used */

	/* accelerometer: 50 Hz, +/-8 g */
	CHECK_WRITE(REG_ACC_CONF_0, ACC_CONF_0_OFF);
	CHECK_WRITE(REG_ACC_CONF_1, ACC_CONF_1_VAL);
	CHECK_WRITE(REG_ACC_CONF_2, ACC_CONF_2_VAL);
	CHECK_WRITE(REG_ACC_CONF_0, ACC_CONF_0_ON);

	/* FIFO: the feature engine (on after reset) locks the FIFO at 512 bytes; it is not used here.
	 * Size first: fifo_cfg cannot be set while fifo_size is 0. These writes also flush the FIFO. */
	CHECK_WRITE(REG_FEAT_ENG_CONF, 0x00);
	CHECK_WRITE(REG_FIFO_CONF_1, FIFO_CONF_1_VAL);
	CHECK_WRITE(REG_FIFO_CONF_0, FIFO_CONF_0_VAL);
	CHECK_WRITE(REG_FIFO_CTRL, FIFO_CTRL_RST);

	err = reg_read(i2c, REG_ACC_CONF_0, acc, sizeof(acc));
	err = err ? err : reg_read(i2c, REG_FIFO_CONF_0, fifo, sizeof(fifo));
	if (err || acc[1] != ACC_CONF_1_VAL || (acc[2] & 0x1F) != ACC_CONF_2_VAL ||
	    (fifo[0] & 0x1F) != FIFO_CONF_0_VAL || (fifo[1] & 0x1F) != FIFO_CONF_1_VAL) {
		printk("I,bma580 read back acc_conf %02x %02x %02x fifo_conf %02x %02x err=%d\n",
		       acc[0], acc[1], acc[2], fifo[0], fifo[1], err);
		return err ? err : -EIO;
	}
	return 0;
}

int bma580_fifo_read(const struct device *i2c, int16_t (*out)[3], int max, bool *overflow)
{
	static uint8_t buf[BMA580_FIFO_MAX_FRAMES * FRAME];
	uint8_t lv[2];

	*overflow = false;
	int err = reg_read(i2c, REG_FIFO_LEVEL_0, lv, sizeof(lv));

	if (err) {
		return err;
	}
	const int level = lv[0] | ((lv[1] & 0x07) << 8);
	const int frames = MIN(MIN(level / PAYLOAD, max), BMA580_FIFO_MAX_FRAMES);

	*overflow = (level >= FIFO_FULL_LEVEL);
	if (frames == 0) {
		return 0;
	}
	/* read whole frames only: a partly read frame would corrupt the next read */
	err = reg_read(i2c, REG_FIFO_DATA_OUT, buf, (uint32_t)(frames * FRAME));
	if (err) {
		return err;
	}
	int n = 0;

	for (int i = 0; i < frames * FRAME; i += FRAME) {
		if (buf[i] == HDR_EMPTY) {
			break;
		}
		if (buf[i] != HDR_ACC_XYZ) {
			return -EBADMSG;          /* out of step with the frames */
		}
		const uint8_t *p = &buf[i + 1];

		for (int k = 0; k < 3; k++) {
			out[n][k] = (int16_t)(p[2 * k] | (p[2 * k + 1] << 8));
		}
		n++;
	}
	return n;
}
```

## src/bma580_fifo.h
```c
/*
 * BMA580 start-up and FIFO streaming for the KNEIL live app (50 Hz, +/-8 g, same settings as
 * BMA580_init() in bma580.c). It follows the datasheet start-up procedure, including the dummy read
 * that selects I2C after a reset. bma580.c itself is not changed (and not used by the KNEIL build).
 */
#ifndef BMA580_FIFO_H
#define BMA580_FIFO_H

#include <stdbool.h>
#include <stdint.h>
#include <zephyr/device.h>

#define BMA580_LSB_PER_G       4096   /* +/-8 g range, 16 bit */
#define BMA580_FIFO_MAX_FRAMES 146    /* 1024-byte FIFO / 7 bytes per frame (header + x, y, z) */

/* Reset and configure the sensor and its FIFO (1024 bytes, x/y/z, 16 bit, oldest frame dropped
 * when full). Returns 0, or a negative error if the FIFO configuration does not read back. */
int bma580_fifo_start(const struct device *i2c);

/* Read all complete frames (at most max) into out[i] = raw x, y, z (sensor axes, LSB).
 * Returns the number of frames, or a negative error (I2C error or unexpected frame: restart the FIFO).
 * *overflow is set if the FIFO was full, i.e. samples were lost before this read. */
int bma580_fifo_read(const struct device *i2c, int16_t (*out)[3], int max, bool *overflow);

#endif /* BMA580_FIFO_H */
```
